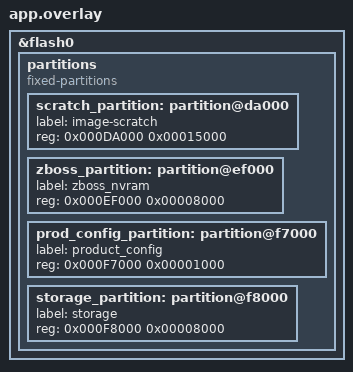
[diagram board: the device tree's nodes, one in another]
/* Copyright (c) 2020 Nordic Semiconductor ASA
 *
 * SPDX-License-Identifier: Apache-2.0
 */

/delete-node/ &scratch_partition;
/delete-node/ &storage_partition;

&flash0 {
	partitions {
		compatible = "fixed-partitions";
		#address-cells = <1>;
		#size-cells = <1>;

		scratch_partition: partition@da000 {
			label = "image-scratch";
			reg = <0x000DA000 0x00015000>;
		};
		zboss_partition: partition@ef000 {
			label = "zboss_nvram";
			reg = <0x000EF000 0x00008000>;
		};
		prod_config_partition: partition@f7000 {
			label = "product_config";
			reg = <0x000F7000 0x00001000>;
		};
		storage_partition: partition@f8000 {
			label = "storage";
			reg = <0x000F8000 0x00008000>;
		};
	};
};
